VERSION ""

NS_ :

BS_:

BU_: PBOX Vehicle

BO_ 912 Vehicle_State: 8 Vehicle
 SG_ TachographVehicleSpeed : 7|16@0+ (0.00390625,0) [0|250.996] "Km/h"  PBOX

BO_ 592 ETC2_TCU_PBOX: 8 Vehicle
 SG_ ETC2_TrmCurrGr : 31|8@0+ (1,-125) [-125|125] "gear value"  PBOX

BO_ 593 VDC2_EBS_PBOX: 8 Vehicle
 SG_ SteeringWheelAngle : 7|16@0+ (0.0009765625,-31.374) [-31.374|31.374] "rad"  PBOX
 SG_ YawRate : 23|16@0+ (0.0001220703125,-3.92) [-3.92|3.92] "rad/s"  PBOX

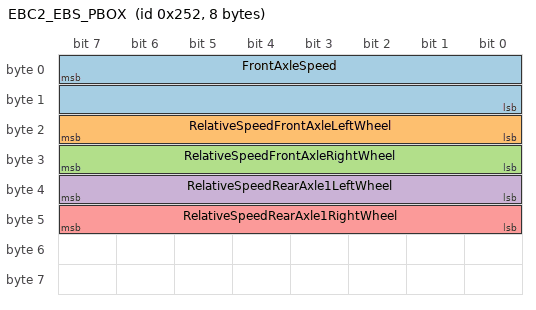
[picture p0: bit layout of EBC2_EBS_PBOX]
BO_ 594 EBC2_EBS_PBOX: 8 Vehicle
 SG_ FrontAxleSpeed : 7|16@0+ (0.00390625,0) [0|250.996] "km/h"  PBOX
 SG_ RelativeSpeedFrontAxleLeftWheel : 23|8@0+ (0.0625,-7.8125) [-7.8125|7.8125] "km/h"  PBOX
 SG_ RelativeSpeedFrontAxleRightWheel : 31|8@0+ (0.0625,-7.8125) [-7.8125|7.8125] "km/h"  PBOX
 SG_ RelativeSpeedRearAxle1LeftWheel : 39|8@0+ (0.0625,-7.8125) [-7.8125|7.8125] "km/h"  PBOX
 SG_ RelativeSpeedRearAxle1RightWheel : 47|8@0+ (0.0625,-7.8125) [-7.8125|7.8125] "km/h"  PBOX

BO_ 913 VDHR_IC_PBOX: 8 Vehicle
 SG_ IC_HResolutionTotalVehiDist : 7|32@0+ (5,0) [0|21474836475] "m"  PBOX

CM_ " ";
CM_ SG_ 592 ETC2_TrmCurrGr "变速箱当前档位";
CM_ SG_ 594 RelativeSpeedFrontAxleLeftWheel "前轴左轮相对速度";
CM_ SG_ 594 RelativeSpeedFrontAxleRightWheel "前轴右轮相对速度";
CM_ SG_ 594 RelativeSpeedRearAxle1LeftWheel "后轴1左轮相对速度";
CM_ SG_ 594 RelativeSpeedRearAxle1RightWheel "后轴1右轮相对速度";
CM_ SG_ 913 IC_HResolutionTotalVehiDist "High Resolution Total Vehicle Distance1
高分辨率的总计里程1";
BA_DEF_ BO_  "GenMsgSendType" ENUM  "Cyclic","Event","IfActive","CE","CA","NoMsgSendType";
BA_DEF_ BO_  "GenMsgCycleTime" INT 0 0;
BA_DEF_ SG_  "GenSigSendType" ENUM  "Cyclic","OnChange","OnWrite","IfActive","OnChangeWithRepetition","OnWriteWithRepetition","IfActiveWithRepetition","NoSigSendType","OnChangeAndIfActive","OnChangeAndIfActiveWithRepetition","CA","CE","Event";
BA_DEF_ SG_  "GenSigStartValue" INT 0 0;
BA_DEF_  "DBName" STRING ;
BA_DEF_ BU_  "NodeLayerModules" STRING ;
BA_DEF_ BU_  "NmNode" ENUM  "Not","Yes";
BA_DEF_  "NmBaseAddress" HEX 0 2047;
BA_DEF_  "NmMessageCount" INT 0 255;
BA_DEF_  "BusType" STRING ;
BA_DEF_DEF_  "GenMsgSendType" "Cyclic";
BA_DEF_DEF_  "GenMsgCycleTime" 0;
BA_DEF_DEF_  "GenSigSendType" "Cyclic";
BA_DEF_DEF_  "GenSigStartValue" 0;
BA_DEF_DEF_  "DBName" "";
BA_DEF_DEF_  "NodeLayerModules" "CANoeILNLVector.dll";
BA_DEF_DEF_  "NmNode" "Not";
BA_DEF_DEF_  "NmBaseAddress" 1024;
BA_DEF_DEF_  "NmMessageCount" 128;
BA_DEF_DEF_  "BusType" "CAN";
BA_ "DBName" "PBOX_CANMatrix";
BA_ "GenMsgCycleTime" BO_ 912 200;
BA_ "GenMsgCycleTime" BO_ 592 100;
BA_ "GenMsgCycleTime" BO_ 593 20;
BA_ "GenMsgCycleTime" BO_ 594 100;
BA_ "GenMsgCycleTime" BO_ 913 200;
BA_ "GenSigStartValue" SG_ 592 ETC2_TrmCurrGr 125;
BA_ "GenSigStartValue" SG_ 593 SteeringWheelAngle 32127;
BA_ "GenSigStartValue" SG_ 593 YawRate 32113;
BA_ "GenSigStartValue" SG_ 594 RelativeSpeedFrontAxleLeftWheel 125;
BA_ "GenSigStartValue" SG_ 594 RelativeSpeedFrontAxleRightWheel 125;
BA_ "GenSigStartValue" SG_ 594 RelativeSpeedRearAxle1LeftWheel 125;
BA_ "GenSigStartValue" SG_ 594 RelativeSpeedRearAxle1RightWheel 125;
